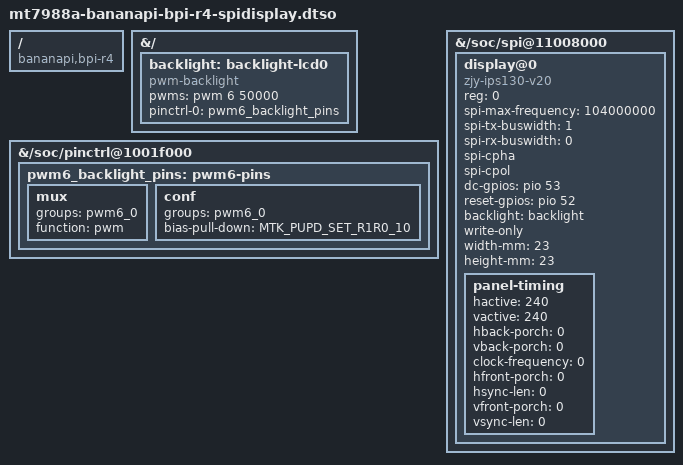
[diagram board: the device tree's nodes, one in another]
// SPDX-License-Identifier: (GPL-2.0 OR MIT)
/*
 * Copyright (C) 2023 MediaTek Inc.
 * Author: Frank Wunderlich <frank-w@public-files.de>
 */

/dts-v1/;
/plugin/;

#include <dt-bindings/gpio/gpio.h>
#include <dt-bindings/pinctrl/mt65xx.h>

/ {
	compatible = "bananapi,bpi-r4", "mediatek,mt7988a";
};

&{/} {
	backlight: backlight-lcd0 {
		compatible = "pwm-backlight";
		pwms = <&pwm 6 50000>;
		pinctrl-names = "default";
		pinctrl-0 = <&pwm6_backlight_pins>;

		status = "okay";
	};
};
 
&{/soc/pinctrl@1001f000} {
	pwm6_backlight_pins: pwm6-pins {
		mux {
			groups = "pwm6_0";
			function = "pwm";
		};

		conf {
			groups = "pwm6_0";
			bias-pull-down = <MTK_PUPD_SET_R1R0_10>;
		};
	};
 };
 
&{/soc/spi@11008000} { //&spi1
	#address-cells = <1>;
	#size-cells = <0>;

	status = "okay";

	display@0 {
		compatible = "zjy-ips130-v20", "panel-mipi-dbi-spi";
		reg = <0>;
		spi-max-frequency = <104000000>;
		spi-tx-buswidth = <1>;
		spi-rx-buswidth = <0>;
		spi-cpha;
		spi-cpol;

		dc-gpios = <&pio 53 GPIO_ACTIVE_HIGH>;
		reset-gpios = <&pio 52 GPIO_ACTIVE_HIGH>;
		backlight = <&backlight>;
		write-only;

		width-mm = <23>;
		height-mm = <23>;

		panel-timing {
			hactive = <240>;
			vactive = <240>;
			hback-porch = <0>;
			vback-porch = <0>;
			clock-frequency = <0>;
			hfront-porch = <0>;
			hsync-len = <0>;
			vfront-porch = <0>;
			vsync-len = <0>;
		};
	};
};
